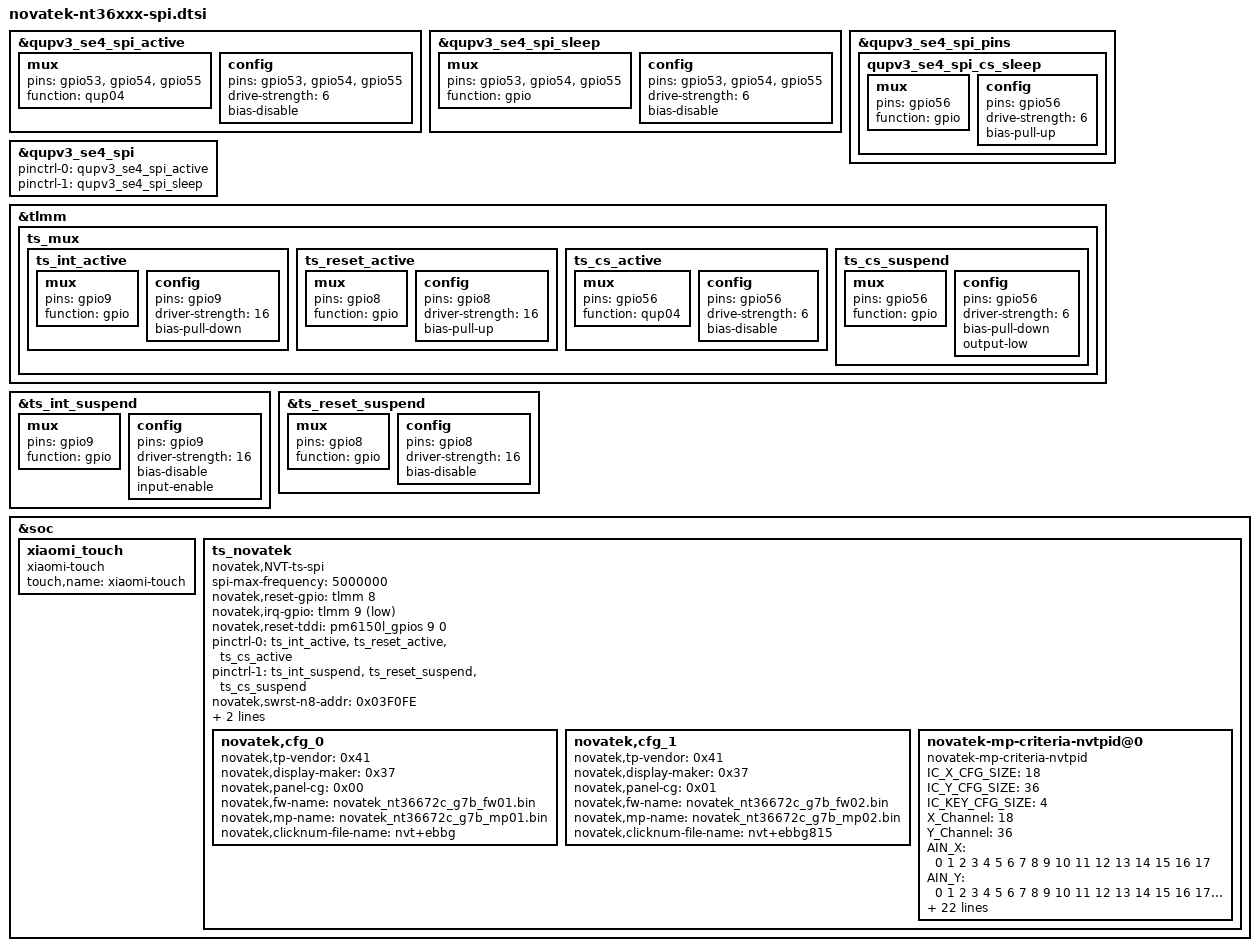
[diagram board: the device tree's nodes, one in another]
/*
 * Copyright (C) 2010 - 2017 Novatek, Inc.
 * Copyright (C) 2021 XiaoMi, Inc.
 *
 * $Revision$
 * $Date$
 *
 * This program is free software; you can redistribute it and/or modify
 * it under the terms of the GNU General Public License as published by
 * the Free Software Foundation; either version 2 of the License, or
 * (at your option) any later version.
 *
 * This program is distributed in the hope that it will be useful, but WITHOUT
 * ANY WARRANTY; without even the implied warranty of MERCHANTABILITY or
 * FITNESS FOR A PARTICULAR PURPOSE.  See the GNU General Public License for
 * more details.
 *
 */

/*spi init*/
&qupv3_se4_spi_active {
	mux {
		pins = "gpio53", "gpio54", "gpio55";
		function = "qup04";
	};

	config {
		pins = "gpio53", "gpio54", "gpio55";
		drive-strength = <6>;
		bias-disable;
	};
};

&qupv3_se4_spi_sleep {
	mux {
		pins = "gpio53", "gpio54", "gpio55";
		function = "gpio";
	};

	config {
		pins = "gpio53", "gpio54", "gpio55";
		drive-strength = <6>;
		bias-disable;
	};
};

&qupv3_se4_spi_pins {
	qupv3_se4_spi_cs_sleep: qupv3_se4_spi_cs_sleep {
	mux {
		pins = "gpio56";
		function = "gpio";
		};

		config {
			pins = "gpio56";
			drive-strength = <6>;
			bias-pull-up; /*CS IDLE PULL UP*/
		};
	};
};

&qupv3_se4_spi {
	pinctrl-0 = <&qupv3_se4_spi_active>;
	pinctrl-1 = <&qupv3_se4_spi_sleep>;
};


/*IC int pin, rst pin init*/
&tlmm {
	ts_mux {
		ts_int_active: ts_int_active {
			mux {
				pins = "gpio9";
				function = "gpio";
			};

			config {
				pins = "gpio9";
				driver-strength = <16>;
				bias-pull-down;
			};
		};

		ts_reset_active: ts_reset_active {
			mux {
				pins = "gpio8";
				function = "gpio";
			};

			config {
				pins = "gpio8";
				driver-strength = <16>;
				bias-pull-up;
			};
		};

		ts_cs_active: ts_cs_active {
			mux {
				pins = "gpio56";
				function = "qup04";
			};

			config {
				pins = "gpio56";
				drive-strength = <6>;
				bias-disable;
			};
		};

		ts_cs_suspend: ts_cs_suspend {
			mux {
				pins = "gpio56";
				function = "gpio";
			};

			config {
				pins = "gpio56";
				driver-strength = <6>;
				bias-pull-down;
				output-low;
			};
		};

	};
};

&ts_int_suspend {
	mux {
		pins = "gpio9";
		function = "gpio";
	};

	config {
		pins = "gpio9";
		driver-strength = <16>;
		bias-disable;
		input-enable;
	};
};

&ts_reset_suspend {
	mux {
		pins = "gpio8";
		function = "gpio";
	};

	config {
		pins = "gpio8";
		driver-strength = <16>;
		bias-disable;
	};
};


/* Novatek device tree node */
&soc {
	xiaomi_touch {
		compatible = "xiaomi-touch";
		status = "ok";
		touch,name = "xiaomi-touch";
	};

	ts_novatek {
			compatible = "novatek,NVT-ts-spi";
			status = "ok";

			spi-max-frequency = <5000000>;	//4800000,9600000,15000000,19200000 5M
			novatek,reset-gpio = <&tlmm 8 0x00>;
			novatek,irq-gpio = <&tlmm 9 0x2001>;
			novatek,reset-tddi = <&pm6150l_gpios 9 0>;
			pinctrl-names = "pmx_ts_active", "pmx_ts_suspend";
			pinctrl-0 = <&ts_int_active &ts_reset_active &ts_cs_active>;
			pinctrl-1 = <&ts_int_suspend &ts_reset_suspend &ts_cs_suspend>;

			/* 672 */
			//novatek,swrst-n8-addr = <0x01F01A>;

			/* 672A */
			novatek,swrst-n8-addr = <0x03F0FE>;
			novatek,spi-rd-fast-addr = <0x03F310>;

			novatek,config-array-size = <2>;
			novatek,cfg_0 {
				novatek,tp-vendor = <0x41>;
				novatek,display-maker = <0x37>;
				novatek,panel-cg = <0x00>;
				novatek,fw-name = "novatek_nt36672c_g7b_fw01.bin";
				novatek,mp-name = "novatek_nt36672c_g7b_mp01.bin";
				novatek,clicknum-file-name = "nvt+ebbg";
			};
			novatek,cfg_1 {
				novatek,tp-vendor = <0x41>;
				novatek,display-maker = <0x37>;
				novatek,panel-cg = <0x01>;
				novatek,fw-name = "novatek_nt36672c_g7b_fw02.bin";
				novatek,mp-name = "novatek_nt36672c_g7b_mp02.bin";
				novatek,clicknum-file-name = "nvt+ebbg815";
			};
			/* MP */
			//novatek,mp-support-dt;


			novatek-mp-criteria-nvtpid@0 {
				#address-cells = <1>;
				#size-cells = <0>;
				compatible = "novatek-mp-criteria-nvtpid";

				/* MP Config */
				IC_X_CFG_SIZE = <18>;
				IC_Y_CFG_SIZE = <36>;
				IC_KEY_CFG_SIZE = <4>;
				X_Channel = <18>;
				Y_Channel = <36>;
				AIN_X = <0 1 2 3 4 5 6 7 8 9 10 11 12 13 14 15 16 17>;
				AIN_Y = <0 1 2 3 4 5 6 7 8 9 10 11 12 13 14 15 16 17
							18 19 20 21 22 23 24 25 26 27 28 29 30 31 32 33 34 35>;
				AIN_KEY = <0 1 2 0xFF>;

				/* MP Criteria */
				PS_Config_Lmt_Short_Rawdata_P = <
					14008 14008 14008 14008 14008 14008 14008 14008 14008 14008 14008 14008 14008 14008 14008 14008 14008 14008
					14008 14008 14008 14008 14008 14008 14008 14008 14008 14008 14008 14008 14008 14008 14008 14008 14008 14008
					14008 14008 14008 14008 14008 14008 14008 14008 14008 14008 14008 14008 14008 14008 14008 14008 14008 14008
					14008 14008 14008 14008 14008 14008 14008 14008 14008 14008 14008 14008 14008 14008 14008 14008 14008 14008
					14008 14008 14008 14008 14008 14008 14008 14008 14008 14008 14008 14008 14008 14008 14008 14008 14008 14008
					14008 14008 14008 14008 14008 14008 14008 14008 14008 14008 14008 14008 14008 14008 14008 14008 14008 14008
					14008 14008 14008 14008 14008 14008 14008 14008 14008 14008 14008 14008 14008 14008 14008 14008 14008 14008
					14008 14008 14008 14008 14008 14008 14008 14008 14008 14008 14008 14008 14008 14008 14008 14008 14008 14008
					14008 14008 14008 14008 14008 14008 14008 14008 14008 14008 14008 14008 14008 14008 14008 14008 14008 14008
					14008 14008 14008 14008 14008 14008 14008 14008 14008 14008 14008 14008 14008 14008 14008 14008 14008 14008
					14008 14008 14008 14008 14008 14008 14008 14008 14008 14008 14008 14008 14008 14008 14008 14008 14008 14008
					14008 14008 14008 14008 14008 14008 14008 14008 14008 14008 14008 14008 14008 14008 14008 14008 14008 14008
					14008 14008 14008 14008 14008 14008 14008 14008 14008 14008 14008 14008 14008 14008 14008 14008 14008 14008
					14008 14008 14008 14008 14008 14008 14008 14008 14008 14008 14008 14008 14008 14008 14008 14008 14008 14008
					14008 14008 14008 14008 14008 14008 14008 14008 14008 14008 14008 14008 14008 14008 14008 14008 14008 14008
					14008 14008 14008 14008 14008 14008 14008 14008 14008 14008 14008 14008 14008 14008 14008 14008 14008 14008
					14008 14008 14008 14008 14008 14008 14008 14008 14008 14008 14008 14008 14008 14008 14008 14008 14008 14008
					14008 14008 14008 14008 14008 14008 14008 14008 14008 14008 14008 14008 14008 14008 14008 14008 14008 14008
					14008 14008 14008 14008 14008 14008 14008 14008 14008 14008 14008 14008 14008 14008 14008 14008 14008 14008
					14008 14008 14008 14008 14008 14008 14008 14008 14008 14008 14008 14008 14008 14008 14008 14008 14008 14008
					14008 14008 14008 14008 14008 14008 14008 14008 14008 14008 14008 14008 14008 14008 14008 14008 14008 14008
					14008 14008 14008 14008 14008 14008 14008 14008 14008 14008 14008 14008 14008 14008 14008 14008 14008 14008
					14008 14008 14008 14008 14008 14008 14008 14008 14008 14008 14008 14008 14008 14008 14008 14008 14008 14008
					14008 14008 14008 14008 14008 14008 14008 14008 14008 14008 14008 14008 14008 14008 14008 14008 14008 14008
					14008 14008 14008 14008 14008 14008 14008 14008 14008 14008 14008 14008 14008 14008 14008 14008 14008 14008
					14008 14008 14008 14008 14008 14008 14008 14008 14008 14008 14008 14008 14008 14008 14008 14008 14008 14008
					14008 14008 14008 14008 14008 14008 14008 14008 14008 14008 14008 14008 14008 14008 14008 14008 14008 14008
					14008 14008 14008 14008 14008 14008 14008 14008 14008 14008 14008 14008 14008 14008 14008 14008 14008 14008
					14008 14008 14008 14008 14008 14008 14008 14008 14008 14008 14008 14008 14008 14008 14008 14008 14008 14008
					14008 14008 14008 14008 14008 14008 14008 14008 14008 14008 14008 14008 14008 14008 14008 14008 14008 14008
					14008 14008 14008 14008 14008 14008 14008 14008 14008 14008 14008 14008 14008 14008 14008 14008 14008 14008
					14008 14008 14008 14008 14008 14008 14008 14008 14008 14008 14008 14008 14008 14008 14008 14008 14008 14008
					14008 14008 14008 14008 14008 14008 14008 14008 14008 14008 14008 14008 14008 14008 14008 14008 14008 14008
					14008 14008 14008 14008 14008 14008 14008 14008 14008 14008 14008 14008 14008 14008 14008 14008 14008 14008
					14008 14008 14008 14008 14008 14008 14008 14008 14008 14008 14008 14008 14008 14008 14008 14008 14008 14008
					14008 14008 14008 14008 14008 14008 14008 14008 14008 14008 14008 14008 14008 14008 14008 14008 14008 14008
					14008 14008 14008>;

				PS_Config_Lmt_Short_Rawdata_N = <
					10000 10000 10000 10000 10000 10000 10000 10000 10000 10000 10000 10000 10000 10000 10000 10000 10000 10000
					10000 10000 10000 10000 10000 10000 10000 10000 10000 10000 10000 10000 10000 10000 10000 10000 10000 10000
					10000 10000 10000 10000 10000 10000 10000 10000 10000 10000 10000 10000 10000 10000 10000 10000 10000 10000
					10000 10000 10000 10000 10000 10000 10000 10000 10000 10000 10000 10000 10000 10000 10000 10000 10000 10000
					10000 10000 10000 10000 10000 10000 10000 10000 10000 10000 10000 10000 10000 10000 10000 10000 10000 10000
					10000 10000 10000 10000 10000 10000 10000 10000 10000 10000 10000 10000 10000 10000 10000 10000 10000 10000
					10000 10000 10000 10000 10000 10000 10000 10000 10000 10000 10000 10000 10000 10000 10000 10000 10000 10000
					10000 10000 10000 10000 10000 10000 10000 10000 10000 10000 10000 10000 10000 10000 10000 10000 10000 10000
					10000 10000 10000 10000 10000 10000 10000 10000 10000 10000 10000 10000 10000 10000 10000 10000 10000 10000
					10000 10000 10000 10000 10000 10000 10000 10000 10000 10000 10000 10000 10000 10000 10000 10000 10000 10000
					10000 10000 10000 10000 10000 10000 10000 10000 10000 10000 10000 10000 10000 10000 10000 10000 10000 10000
					10000 10000 10000 10000 10000 10000 10000 10000 10000 10000 10000 10000 10000 10000 10000 10000 10000 10000
					10000 10000 10000 10000 10000 10000 10000 10000 10000 10000 10000 10000 10000 10000 10000 10000 10000 10000
					10000 10000 10000 10000 10000 10000 10000 10000 10000 10000 10000 10000 10000 10000 10000 10000 10000 10000
					10000 10000 10000 10000 10000 10000 10000 10000 10000 10000 10000 10000 10000 10000 10000 10000 10000 10000
					10000 10000 10000 10000 10000 10000 10000 10000 10000 10000 10000 10000 10000 10000 10000 10000 10000 10000
					10000 10000 10000 10000 10000 10000 10000 10000 10000 10000 10000 10000 10000 10000 10000 10000 10000 10000
					10000 10000 10000 10000 10000 10000 10000 10000 10000 10000 10000 10000 10000 10000 10000 10000 10000 10000
					10000 10000 10000 10000 10000 10000 10000 10000 10000 10000 10000 10000 10000 10000 10000 10000 10000 10000
					10000 10000 10000 10000 10000 10000 10000 10000 10000 10000 10000 10000 10000 10000 10000 10000 10000 10000
					10000 10000 10000 10000 10000 10000 10000 10000 10000 10000 10000 10000 10000 10000 10000 10000 10000 10000
					10000 10000 10000 10000 10000 10000 10000 10000 10000 10000 10000 10000 10000 10000 10000 10000 10000 10000
					10000 10000 10000 10000 10000 10000 10000 10000 10000 10000 10000 10000 10000 10000 10000 10000 10000 10000
					10000 10000 10000 10000 10000 10000 10000 10000 10000 10000 10000 10000 10000 10000 10000 10000 10000 10000
					10000 10000 10000 10000 10000 10000 10000 10000 10000 10000 10000 10000 10000 10000 10000 10000 10000 10000
					10000 10000 10000 10000 10000 10000 10000 10000 10000 10000 10000 10000 10000 10000 10000 10000 10000 10000
					10000 10000 10000 10000 10000 10000 10000 10000 10000 10000 10000 10000 10000 10000 10000 10000 10000 10000
					10000 10000 10000 10000 10000 10000 10000 10000 10000 10000 10000 10000 10000 10000 10000 10000 10000 10000
					10000 10000 10000 10000 10000 10000 10000 10000 10000 10000 10000 10000 10000 10000 10000 10000 10000 10000
					10000 10000 10000 10000 10000 10000 10000 10000 10000 10000 10000 10000 10000 10000 10000 10000 10000 10000
					10000 10000 10000 10000 10000 10000 10000 10000 10000 10000 10000 10000 10000 10000 10000 10000 10000 10000
					10000 10000 10000 10000 10000 10000 10000 10000 10000 10000 10000 10000 10000 10000 10000 10000 10000 10000
					10000 10000 10000 10000 10000 10000 10000 10000 10000 10000 10000 10000 10000 10000 10000 10000 10000 10000
					10000 10000 10000 10000 10000 10000 10000 10000 10000 10000 10000 10000 10000 10000 10000 10000 10000 10000
					10000 10000 10000 10000 10000 10000 10000 10000 10000 10000 10000 10000 10000 10000 10000 10000 10000 10000
					10000 10000 10000 10000 10000 10000 10000 10000 10000 10000 10000 10000 10000 10000 10000 10000 10000 10000
					10000 10000 10000>;

				PS_Config_Lmt_Open_Rawdata_P = <
					4096 4096 4096 4096 4096 4096 4096 4096 4096 4096 4096 4096 4096 4096 4096 4096 4096 4096
					4096 4096 4096 4096 4096 4096 4096 4096 4096 4096 4096 4096 4096 4096 4096 4096 4096 4096
					4096 4096 4096 4096 4096 4096 4096 4096 4096 4096 4096 4096 4096 4096 4096 4096 4096 4096
					4096 4096 4096 4096 4096 4096 4096 4096 4096 4096 4096 4096 4096 4096 4096 4096 4096 4096
					4096 4096 4096 4096 4096 4096 4096 4096 4096 4096 4096 4096 4096 4096 4096 4096 4096 4096
					4096 4096 4096 4096 4096 4096 4096 4096 4096 4096 4096 4096 4096 4096 4096 4096 4096 4096
					4096 4096 4096 4096 4096 4096 4096 4096 4096 4096 4096 4096 4096 4096 4096 4096 4096 4096
					4096 4096 4096 4096 4096 4096 4096 4096 4096 4096 4096 4096 4096 4096 4096 4096 4096 4096
					4096 4096 4096 4096 4096 4096 4096 4096 4096 4096 4096 4096 4096 4096 4096 4096 4096 4096
					4096 4096 4096 4096 4096 4096 4096 4096 4096 4096 4096 4096 4096 4096 4096 4096 4096 4096
					4096 4096 4096 4096 4096 4096 4096 4096 4096 4096 4096 4096 4096 4096 4096 4096 4096 4096
					4096 4096 4096 4096 4096 4096 4096 4096 4096 4096 4096 4096 4096 4096 4096 4096 4096 4096
					4096 4096 4096 4096 4096 4096 4096 4096 4096 4096 4096 4096 4096 4096 4096 4096 4096 4096
					4096 4096 4096 4096 4096 4096 4096 4096 4096 4096 4096 4096 4096 4096 4096 4096 4096 4096
					4096 4096 4096 4096 4096 4096 4096 4096 4096 4096 4096 4096 4096 4096 4096 4096 4096 4096
					4096 4096 4096 4096 4096 4096 4096 4096 4096 4096 4096 4096 4096 4096 4096 4096 4096 4096
					4096 4096 4096 4096 4096 4096 4096 4096 4096 4096 4096 4096 4096 4096 4096 4096 4096 4096
					4096 4096 4096 4096 4096 4096 4096 4096 4096 4096 4096 4096 4096 4096 4096 4096 4096 4096
					4096 4096 4096 4096 4096 4096 4096 4096 4096 4096 4096 4096 4096 4096 4096 4096 4096 4096
					4096 4096 4096 4096 4096 4096 4096 4096 4096 4096 4096 4096 4096 4096 4096 4096 4096 4096
					4096 4096 4096 4096 4096 4096 4096 4096 4096 4096 4096 4096 4096 4096 4096 4096 4096 4096
					4096 4096 4096 4096 4096 4096 4096 4096 4096 4096 4096 4096 4096 4096 4096 4096 4096 4096
					4096 4096 4096 4096 4096 4096 4096 4096 4096 4096 4096 4096 4096 4096 4096 4096 4096 4096
					4096 4096 4096 4096 4096 4096 4096 4096 4096 4096 4096 4096 4096 4096 4096 4096 4096 4096
					4096 4096 4096 4096 4096 4096 4096 4096 4096 4096 4096 4096 4096 4096 4096 4096 4096 4096
					4096 4096 4096 4096 4096 4096 4096 4096 4096 4096 4096 4096 4096 4096 4096 4096 4096 4096
					4096 4096 4096 4096 4096 4096 4096 4096 4096 4096 4096 4096 4096 4096 4096 4096 4096 4096
					4096 4096 4096 4096 4096 4096 4096 4096 4096 4096 4096 4096 4096 4096 4096 4096 4096 4096
					4096 4096 4096 4096 4096 4096 4096 4096 4096 4096 4096 4096 4096 4096 4096 4096 4096 4096
					4096 4096 4096 4096 4096 4096 4096 4096 4096 4096 4096 4096 4096 4096 4096 4096 4096 4096
					4096 4096 4096 4096 4096 4096 4096 4096 4096 4096 4096 4096 4096 4096 4096 4096 4096 4096
					4096 4096 4096 4096 4096 4096 4096 4096 4096 4096 4096 4096 4096 4096 4096 4096 4096 4096
					4096 4096 4096 4096 4096 4096 4096 4096 4096 4096 4096 4096 4096 4096 4096 4096 4096 4096
					4096 4096 4096 4096 4096 4096 4096 4096 4096 4096 4096 4096 4096 4096 4096 4096 4096 4096
					4096 4096 4096 4096 4096 4096 4096 4096 4096 4096 4096 4096 4096 4096 4096 4096 4096 4096
					4096 4096 4096 4096 4096 4096 4096 4096 4096 4096 4096 4096 4096 4096 4096 4096 4096 4096
					4096 4096 4096>;

				PS_Config_Lmt_Open_Rawdata_N = <
					50 50 50 50 50 50 50 50 50 50 50 50 50 50 50 50 50 50
					50 50 50 50 50 50 50 50 50 50 50 50 50 50 50 50 50 50
					50 50 50 50 50 50 50 50 50 50 50 50 50 50 50 50 50 50
					50 50 50 50 50 50 50 50 50 50 50 50 50 50 50 50 50 50
					50 50 50 50 50 50 50 50 50 50 50 50 50 50 50 50 50 50
					50 50 50 50 50 50 50 50 50 50 50 50 50 50 50 50 50 50
					50 50 50 50 50 50 50 50 50 50 50 50 50 50 50 50 50 50
					50 50 50 50 50 50 50 50 50 50 50 50 50 50 50 50 50 50
					50 50 50 50 50 50 50 50 50 50 50 50 50 50 50 50 50 50
					50 50 50 50 50 50 50 50 50 50 50 50 50 50 50 50 50 50
					50 50 50 50 50 50 50 50 50 50 50 50 50 50 50 50 50 50
					50 50 50 50 50 50 50 50 50 50 50 50 50 50 50 50 50 50
					50 50 50 50 50 50 50 50 50 50 50 50 50 50 50 50 50 50
					50 50 50 50 50 50 50 50 50 50 50 50 50 50 50 50 50 50
					50 50 50 50 50 50 50 50 50 50 50 50 50 50 50 50 50 50
					50 50 50 50 50 50 50 50 50 50 50 50 50 50 50 50 50 50
					50 50 50 50 50 50 50 50 50 50 50 50 50 50 50 50 50 50
					50 50 50 50 50 50 50 50 50 50 50 50 50 50 50 50 50 50
					50 50 50 50 50 50 50 50 50 50 50 50 50 50 50 50 50 50
					50 50 50 50 50 50 50 50 50 50 50 50 50 50 50 50 50 50
					50 50 50 50 50 50 50 50 50 50 50 50 50 50 50 50 50 50
					50 50 50 50 50 50 50 50 50 50 50 50 50 50 50 50 50 50
					50 50 50 50 50 50 50 50 50 50 50 50 50 50 50 50 50 50
					50 50 50 50 50 50 50 50 50 50 50 50 50 50 50 50 50 50
					50 50 50 50 50 50 50 50 50 50 50 50 50 50 50 50 50 50
					50 50 50 50 50 50 50 50 50 50 50 50 50 50 50 50 50 50
					50 50 50 50 50 50 50 50 50 50 50 50 50 50 50 50 50 50
					50 50 50 50 50 50 50 50 50 50 50 50 50 50 50 50 50 50
					50 50 50 50 50 50 50 50 50 50 50 50 50 50 50 50 50 50
					50 50 50 50 50 50 50 50 50 50 50 50 50 50 50 50 50 50
					50 50 50 50 50 50 50 50 50 50 50 50 50 50 50 50 50 50
					50 50 50 50 50 50 50 50 50 50 50 50 50 50 50 50 50 50
					50 50 50 50 50 50 50 50 50 50 50 50 50 50 50 50 50 50
					50 50 50 50 50 50 50 50 50 50 50 50 50 50 50 50 50 50
					50 50 50 50 50 50 50 50 50 50 50 50 50 50 50 50 50 50
					50 50 50 50 50 50 50 50 50 50 50 50 50 50 50 50 50 50
					50 50 50>;

				PS_Config_Lmt_FW_Rawdata_P = <
					1920 1920 1920 1920 1920 1920 1920 1920 1920 1920 1920 1920 1920 1920 1920 1920 1920 1920
					1920 1920 1920 1920 1920 1920 1920 1920 1920 1920 1920 1920 1920 1920 1920 1920 1920 1920
					1920 1920 1920 1920 1920 1920 1920 1920 1920 1920 1920 1920 1920 1920 1920 1920 1920 1920
					1920 1920 1920 1920 1920 1920 1920 1920 1920 1920 1920 1920 1920 1920 1920 1920 1920 1920
					1920 1920 1920 1920 1920 1920 1920 1920 1920 1920 1920 1920 1920 1920 1920 1920 1920 1920
					1920 1920 1920 1920 1920 1920 1920 1920 1920 1920 1920 1920 1920 1920 1920 1920 1920 1920
					1920 1920 1920 1920 1920 1920 1920 1920 1920 1920 1920 1920 1920 1920 1920 1920 1920 1920
					1920 1920 1920 1920 1920 1920 1920 1920 1920 1920 1920 1920 1920 1920 1920 1920 1920 1920
					1920 1920 1920 1920 1920 1920 1920 1920 1920 1920 1920 1920 1920 1920 1920 1920 1920 1920
					1920 1920 1920 1920 1920 1920 1920 1920 1920 1920 1920 1920 1920 1920 1920 1920 1920 1920
					1920 1920 1920 1920 1920 1920 1920 1920 1920 1920 1920 1920 1920 1920 1920 1920 1920 1920
					1920 1920 1920 1920 1920 1920 1920 1920 1920 1920 1920 1920 1920 1920 1920 1920 1920 1920
					1920 1920 1920 1920 1920 1920 1920 1920 1920 1920 1920 1920 1920 1920 1920 1920 1920 1920
					1920 1920 1920 1920 1920 1920 1920 1920 1920 1920 1920 1920 1920 1920 1920 1920 1920 1920
					1920 1920 1920 1920 1920 1920 1920 1920 1920 1920 1920 1920 1920 1920 1920 1920 1920 1920
					1920 1920 1920 1920 1920 1920 1920 1920 1920 1920 1920 1920 1920 1920 1920 1920 1920 1920
					1920 1920 1920 1920 1920 1920 1920 1920 1920 1920 1920 1920 1920 1920 1920 1920 1920 1920
					1920 1920 1920 1920 1920 1920 1920 1920 1920 1920 1920 1920 1920 1920 1920 1920 1920 1920
					1920 1920 1920 1920 1920 1920 1920 1920 1920 1920 1920 1920 1920 1920 1920 1920 1920 1920
					1920 1920 1920 1920 1920 1920 1920 1920 1920 1920 1920 1920 1920 1920 1920 1920 1920 1920
					1920 1920 1920 1920 1920 1920 1920 1920 1920 1920 1920 1920 1920 1920 1920 1920 1920 1920
					1920 1920 1920 1920 1920 1920 1920 1920 1920 1920 1920 1920 1920 1920 1920 1920 1920 1920
					1920 1920 1920 1920 1920 1920 1920 1920 1920 1920 1920 1920 1920 1920 1920 1920 1920 1920
					1920 1920 1920 1920 1920 1920 1920 1920 1920 1920 1920 1920 1920 1920 1920 1920 1920 1920
					1920 1920 1920 1920 1920 1920 1920 1920 1920 1920 1920 1920 1920 1920 1920 1920 1920 1920
					1920 1920 1920 1920 1920 1920 1920 1920 1920 1920 1920 1920 1920 1920 1920 1920 1920 1920
					1920 1920 1920 1920 1920 1920 1920 1920 1920 1920 1920 1920 1920 1920 1920 1920 1920 1920
					1920 1920 1920 1920 1920 1920 1920 1920 1920 1920 1920 1920 1920 1920 1920 1920 1920 1920
					1920 1920 1920 1920 1920 1920 1920 1920 1920 1920 1920 1920 1920 1920 1920 1920 1920 1920
					1920 1920 1920 1920 1920 1920 1920 1920 1920 1920 1920 1920 1920 1920 1920 1920 1920 1920
					1920 1920 1920 1920 1920 1920 1920 1920 1920 1920 1920 1920 1920 1920 1920 1920 1920 1920
					1920 1920 1920 1920 1920 1920 1920 1920 1920 1920 1920 1920 1920 1920 1920 1920 1920 1920
					1920 1920 1920 1920 1920 1920 1920 1920 1920 1920 1920 1920 1920 1920 1920 1920 1920 1920
					1920 1920 1920 1920 1920 1920 1920 1920 1920 1920 1920 1920 1920 1920 1920 1920 1920 1920
					1920 1920 1920 1920 1920 1920 1920 1920 1920 1920 1920 1920 1920 1920 1920 1920 1920 1920
					1920 1920 1920 1920 1920 1920 1920 1920 1920 1920 1920 1920 1920 1920 1920 1920 1920 1920
					1920 1920 1920>;

				PS_Config_Lmt_FW_Rawdata_N = <
					240 240 240 240 240 240 240 240 240 240 240 240 240 240 240 240 240 240
					240 240 240 240 240 240 240 240 240 240 240 240 240 240 240 240 240 240
					240 240 240 240 240 240 240 240 240 240 240 240 240 240 240 240 240 240
					240 240 240 240 240 240 240 240 240 240 240 240 240 240 240 240 240 240
					240 240 240 240 240 240 240 240 240 240 240 240 240 240 240 240 240 240
					240 240 240 240 240 240 240 240 240 240 240 240 240 240 240 240 240 240
					240 240 240 240 240 240 240 240 240 240 240 240 240 240 240 240 240 240
					240 240 240 240 240 240 240 240 240 240 240 240 240 240 240 240 240 240
					240 240 240 240 240 240 240 240 240 240 240 240 240 240 240 240 240 240
					240 240 240 240 240 240 240 240 240 240 240 240 240 240 240 240 240 240
					240 240 240 240 240 240 240 240 240 240 240 240 240 240 240 240 240 240
					240 240 240 240 240 240 240 240 240 240 240 240 240 240 240 240 240 240
					240 240 240 240 240 240 240 240 240 240 240 240 240 240 240 240 240 240
					240 240 240 240 240 240 240 240 240 240 240 240 240 240 240 240 240 240
					240 240 240 240 240 240 240 240 240 240 240 240 240 240 240 240 240 240
					240 240 240 240 240 240 240 240 240 240 240 240 240 240 240 240 240 240
					240 240 240 240 240 240 240 240 240 240 240 240 240 240 240 240 240 240
					240 240 240 240 240 240 240 240 240 240 240 240 240 240 240 240 240 240
					240 240 240 240 240 240 240 240 240 240 240 240 240 240 240 240 240 240
					240 240 240 240 240 240 240 240 240 240 240 240 240 240 240 240 240 240
					240 240 240 240 240 240 240 240 240 240 240 240 240 240 240 240 240 240
					240 240 240 240 240 240 240 240 240 240 240 240 240 240 240 240 240 240
					240 240 240 240 240 240 240 240 240 240 240 240 240 240 240 240 240 240
					240 240 240 240 240 240 240 240 240 240 240 240 240 240 240 240 240 240
					240 240 240 240 240 240 240 240 240 240 240 240 240 240 240 240 240 240
					240 240 240 240 240 240 240 240 240 240 240 240 240 240 240 240 240 240
					240 240 240 240 240 240 240 240 240 240 240 240 240 240 240 240 240 240
					240 240 240 240 240 240 240 240 240 240 240 240 240 240 240 240 240 240
					240 240 240 240 240 240 240 240 240 240 240 240 240 240 240 240 240 240
					240 240 240 240 240 240 240 240 240 240 240 240 240 240 240 240 240 240
					240 240 240 240 240 240 240 240 240 240 240 240 240 240 240 240 240 240
					240 240 240 240 240 240 240 240 240 240 240 240 240 240 240 240 240 240
					240 240 240 240 240 240 240 240 240 240 240 240 240 240 240 240 240 240
					240 240 240 240 240 240 240 240 240 240 240 240 240 240 240 240 240 240
					240 240 240 240 240 240 240 240 240 240 240 240 240 240 240 240 240 240
					240 240 240 240 240 240 240 240 240 240 240 240 240 240 240 240 240 240
					240 240 240>;

				PS_Config_Lmt_FW_CC_P = <
					314 314 314 314 314 314 314 314 314 314 314 314 314 314 314 314 314 314
					314 314 314 314 314 314 314 314 314 314 314 314 314 314 314 314 314 314
					314 314 314 314 314 314 314 314 314 314 314 314 314 314 314 314 314 314
					314 314 314 314 314 314 314 314 314 314 314 314 314 314 314 314 314 314
					314 314 314 314 314 314 314 314 314 314 314 314 314 314 314 314 314 314
					314 314 314 314 314 314 314 314 314 314 314 314 314 314 314 314 314 314
					314 314 314 314 314 314 314 314 314 314 314 314 314 314 314 314 314 314
					314 314 314 314 314 314 314 314 314 314 314 314 314 314 314 314 314 314
					314 314 314 314 314 314 314 314 314 314 314 314 314 314 314 314 314 314
					314 314 314 314 314 314 314 314 314 314 314 314 314 314 314 314 314 314
					314 314 314 314 314 314 314 314 314 314 314 314 314 314 314 314 314 314
					314 314 314 314 314 314 314 314 314 314 314 314 314 314 314 314 314 314
					314 314 314 314 314 314 314 314 314 314 314 314 314 314 314 314 314 314
					314 314 314 314 314 314 314 314 314 314 314 314 314 314 314 314 314 314
					314 314 314 314 314 314 314 314 314 314 314 314 314 314 314 314 314 314
					314 314 314 314 314 314 314 314 314 314 314 314 314 314 314 314 314 314
					314 314 314 314 314 314 314 314 314 314 314 314 314 314 314 314 314 314
					314 314 314 314 314 314 314 314 314 314 314 314 314 314 314 314 314 314
					314 314 314 314 314 314 314 314 314 314 314 314 314 314 314 314 314 314
					314 314 314 314 314 314 314 314 314 314 314 314 314 314 314 314 314 314
					314 314 314 314 314 314 314 314 314 314 314 314 314 314 314 314 314 314
					314 314 314 314 314 314 314 314 314 314 314 314 314 314 314 314 314 314
					314 314 314 314 314 314 314 314 314 314 314 314 314 314 314 314 314 314
					314 314 314 314 314 314 314 314 314 314 314 314 314 314 314 314 314 314
					314 314 314 314 314 314 314 314 314 314 314 314 314 314 314 314 314 314
					314 314 314 314 314 314 314 314 314 314 314 314 314 314 314 314 314 314
					314 314 314 314 314 314 314 314 314 314 314 314 314 314 314 314 314 314
					314 314 314 314 314 314 314 314 314 314 314 314 314 314 314 314 314 314
					314 314 314 314 314 314 314 314 314 314 314 314 314 314 314 314 314 314
					314 314 314 314 314 314 314 314 314 314 314 314 314 314 314 314 314 314
					314 314 314 314 314 314 314 314 314 314 314 314 314 314 314 314 314 314
					314 314 314 314 314 314 314 314 314 314 314 314 314 314 314 314 314 314
					314 314 314 314 314 314 314 314 314 314 314 314 314 314 314 314 314 314
					314 314 314 314 314 314 314 314 314 314 314 314 314 314 314 314 314 314
					314 314 314 314 314 314 314 314 314 314 314 314 314 314 314 314 314 314
					314 314 314 314 314 314 314 314 314 314 314 314 314 314 314 314 314 314
					314 314 314>;

				PS_Config_Lmt_FW_CC_N = <
					30 30 30 30 30 30 30 30 30 30 30 30 30 30 30 30 30 30
					30 30 30 30 30 30 30 30 30 30 30 30 30 30 30 30 30 30
					30 30 30 30 30 30 30 30 30 30 30 30 30 30 30 30 30 30
					30 30 30 30 30 30 30 30 30 30 30 30 30 30 30 30 30 30
					30 30 30 30 30 30 30 30 30 30 30 30 30 30 30 30 30 30
					30 30 30 30 30 30 30 30 30 30 30 30 30 30 30 30 30 30
					30 30 30 30 30 30 30 30 30 30 30 30 30 30 30 30 30 30
					30 30 30 30 30 30 30 30 30 30 30 30 30 30 30 30 30 30
					30 30 30 30 30 30 30 30 30 30 30 30 30 30 30 30 30 30
					30 30 30 30 30 30 30 30 30 30 30 30 30 30 30 30 30 30
					30 30 30 30 30 30 30 30 30 30 30 30 30 30 30 30 30 30
					30 30 30 30 30 30 30 30 30 30 30 30 30 30 30 30 30 30
					30 30 30 30 30 30 30 30 30 30 30 30 30 30 30 30 30 30
					30 30 30 30 30 30 30 30 30 30 30 30 30 30 30 30 30 30
					30 30 30 30 30 30 30 30 30 30 30 30 30 30 30 30 30 30
					30 30 30 30 30 30 30 30 30 30 30 30 30 30 30 30 30 30
					30 30 30 30 30 30 30 30 30 30 30 30 30 30 30 30 30 30
					30 30 30 30 30 30 30 30 30 30 30 30 30 30 30 30 30 30
					30 30 30 30 30 30 30 30 30 30 30 30 30 30 30 30 30 30
					30 30 30 30 30 30 30 30 30 30 30 30 30 30 30 30 30 30
					30 30 30 30 30 30 30 30 30 30 30 30 30 30 30 30 30 30
					30 30 30 30 30 30 30 30 30 30 30 30 30 30 30 30 30 30
					30 30 30 30 30 30 30 30 30 30 30 30 30 30 30 30 30 30
					30 30 30 30 30 30 30 30 30 30 30 30 30 30 30 30 30 30
					30 30 30 30 30 30 30 30 30 30 30 30 30 30 30 30 30 30
					30 30 30 30 30 30 30 30 30 30 30 30 30 30 30 30 30 30
					30 30 30 30 30 30 30 30 30 30 30 30 30 30 30 30 30 30
					30 30 30 30 30 30 30 30 30 30 30 30 30 30 30 30 30 30
					30 30 30 30 30 30 30 30 30 30 30 30 30 30 30 30 30 30
					30 30 30 30 30 30 30 30 30 30 30 30 30 30 30 30 30 30
					30 30 30 30 30 30 30 30 30 30 30 30 30 30 30 30 30 30
					30 30 30 30 30 30 30 30 30 30 30 30 30 30 30 30 30 30
					30 30 30 30 30 30 30 30 30 30 30 30 30 30 30 30 30 30
					30 30 30 30 30 30 30 30 30 30 30 30 30 30 30 30 30 30
					30 30 30 30 30 30 30 30 30 30 30 30 30 30 30 30 30 30
					30 30 30 30 30 30 30 30 30 30 30 30 30 30 30 30 30 30
					30 30 30>;

				PS_Config_Lmt_FW_Diff_P = <
					75 75 75 75 75 75 75 75 75 75 75 75 75 75 75 75 75 75
					75 75 75 75 75 75 75 75 75 75 75 75 75 75 75 75 75 75
					75 75 75 75 75 75 75 75 75 75 75 75 75 75 75 75 75 75
					75 75 75 75 75 75 75 75 75 75 75 75 75 75 75 75 75 75
					75 75 75 75 75 75 75 75 75 75 75 75 75 75 75 75 75 75
					75 75 75 75 75 75 75 75 75 75 75 75 75 75 75 75 75 75
					75 75 75 75 75 75 75 75 75 75 75 75 75 75 75 75 75 75
					75 75 75 75 75 75 75 75 75 75 75 75 75 75 75 75 75 75
					75 75 75 75 75 75 75 75 75 75 75 75 75 75 75 75 75 75
					75 75 75 75 75 75 75 75 75 75 75 75 75 75 75 75 75 75
					75 75 75 75 75 75 75 75 75 75 75 75 75 75 75 75 75 75
					75 75 75 75 75 75 75 75 75 75 75 75 75 75 75 75 75 75
					75 75 75 75 75 75 75 75 75 75 75 75 75 75 75 75 75 75
					75 75 75 75 75 75 75 75 75 75 75 75 75 75 75 75 75 75
					75 75 75 75 75 75 75 75 75 75 75 75 75 75 75 75 75 75
					75 75 75 75 75 75 75 75 75 75 75 75 75 75 75 75 75 75
					75 75 75 75 75 75 75 75 75 75 75 75 75 75 75 75 75 75
					75 75 75 75 75 75 75 75 75 75 75 75 75 75 75 75 75 75
					75 75 75 75 75 75 75 75 75 75 75 75 75 75 75 75 75 75
					75 75 75 75 75 75 75 75 75 75 75 75 75 75 75 75 75 75
					75 75 75 75 75 75 75 75 75 75 75 75 75 75 75 75 75 75
					75 75 75 75 75 75 75 75 75 75 75 75 75 75 75 75 75 75
					75 75 75 75 75 75 75 75 75 75 75 75 75 75 75 75 75 75
					75 75 75 75 75 75 75 75 75 75 75 75 75 75 75 75 75 75
					75 75 75 75 75 75 75 75 75 75 75 75 75 75 75 75 75 75
					75 75 75 75 75 75 75 75 75 75 75 75 75 75 75 75 75 75
					75 75 75 75 75 75 75 75 75 75 75 75 75 75 75 75 75 75
					75 75 75 75 75 75 75 75 75 75 75 75 75 75 75 75 75 75
					75 75 75 75 75 75 75 75 75 75 75 75 75 75 75 75 75 75
					75 75 75 75 75 75 75 75 75 75 75 75 75 75 75 75 75 75
					75 75 75 75 75 75 75 75 75 75 75 75 75 75 75 75 75 75
					75 75 75 75 75 75 75 75 75 75 75 75 75 75 75 75 75 75
					75 75 75 75 75 75 75 75 75 75 75 75 75 75 75 75 75 75
					75 75 75 75 75 75 75 75 75 75 75 75 75 75 75 75 75 75
					75 75 75 75 75 75 75 75 75 75 75 75 75 75 75 75 75 75
					75 75 75 75 75 75 75 75 75 75 75 75 75 75 75 75 75 75
					75 75 75>;

				PS_Config_Lmt_FW_Diff_N = <
					(-75) (-75) (-75) (-75) (-75) (-75) (-75) (-75) (-75) (-75) (-75) (-75) (-75) (-75) (-75) (-75) (-75) (-75)
					(-75) (-75) (-75) (-75) (-75) (-75) (-75) (-75) (-75) (-75) (-75) (-75) (-75) (-75) (-75) (-75) (-75) (-75)
					(-75) (-75) (-75) (-75) (-75) (-75) (-75) (-75) (-75) (-75) (-75) (-75) (-75) (-75) (-75) (-75) (-75) (-75)
					(-75) (-75) (-75) (-75) (-75) (-75) (-75) (-75) (-75) (-75) (-75) (-75) (-75) (-75) (-75) (-75) (-75) (-75)
					(-75) (-75) (-75) (-75) (-75) (-75) (-75) (-75) (-75) (-75) (-75) (-75) (-75) (-75) (-75) (-75) (-75) (-75)
					(-75) (-75) (-75) (-75) (-75) (-75) (-75) (-75) (-75) (-75) (-75) (-75) (-75) (-75) (-75) (-75) (-75) (-75)
					(-75) (-75) (-75) (-75) (-75) (-75) (-75) (-75) (-75) (-75) (-75) (-75) (-75) (-75) (-75) (-75) (-75) (-75)
					(-75) (-75) (-75) (-75) (-75) (-75) (-75) (-75) (-75) (-75) (-75) (-75) (-75) (-75) (-75) (-75) (-75) (-75)
					(-75) (-75) (-75) (-75) (-75) (-75) (-75) (-75) (-75) (-75) (-75) (-75) (-75) (-75) (-75) (-75) (-75) (-75)
					(-75) (-75) (-75) (-75) (-75) (-75) (-75) (-75) (-75) (-75) (-75) (-75) (-75) (-75) (-75) (-75) (-75) (-75)
					(-75) (-75) (-75) (-75) (-75) (-75) (-75) (-75) (-75) (-75) (-75) (-75) (-75) (-75) (-75) (-75) (-75) (-75)
					(-75) (-75) (-75) (-75) (-75) (-75) (-75) (-75) (-75) (-75) (-75) (-75) (-75) (-75) (-75) (-75) (-75) (-75)
					(-75) (-75) (-75) (-75) (-75) (-75) (-75) (-75) (-75) (-75) (-75) (-75) (-75) (-75) (-75) (-75) (-75) (-75)
					(-75) (-75) (-75) (-75) (-75) (-75) (-75) (-75) (-75) (-75) (-75) (-75) (-75) (-75) (-75) (-75) (-75) (-75)
					(-75) (-75) (-75) (-75) (-75) (-75) (-75) (-75) (-75) (-75) (-75) (-75) (-75) (-75) (-75) (-75) (-75) (-75)
					(-75) (-75) (-75) (-75) (-75) (-75) (-75) (-75) (-75) (-75) (-75) (-75) (-75) (-75) (-75) (-75) (-75) (-75)
					(-75) (-75) (-75) (-75) (-75) (-75) (-75) (-75) (-75) (-75) (-75) (-75) (-75) (-75) (-75) (-75) (-75) (-75)
					(-75) (-75) (-75) (-75) (-75) (-75) (-75) (-75) (-75) (-75) (-75) (-75) (-75) (-75) (-75) (-75) (-75) (-75)
					(-75) (-75) (-75) (-75) (-75) (-75) (-75) (-75) (-75) (-75) (-75) (-75) (-75) (-75) (-75) (-75) (-75) (-75)
					(-75) (-75) (-75) (-75) (-75) (-75) (-75) (-75) (-75) (-75) (-75) (-75) (-75) (-75) (-75) (-75) (-75) (-75)
					(-75) (-75) (-75) (-75) (-75) (-75) (-75) (-75) (-75) (-75) (-75) (-75) (-75) (-75) (-75) (-75) (-75) (-75)
					(-75) (-75) (-75) (-75) (-75) (-75) (-75) (-75) (-75) (-75) (-75) (-75) (-75) (-75) (-75) (-75) (-75) (-75)
					(-75) (-75) (-75) (-75) (-75) (-75) (-75) (-75) (-75) (-75) (-75) (-75) (-75) (-75) (-75) (-75) (-75) (-75)
					(-75) (-75) (-75) (-75) (-75) (-75) (-75) (-75) (-75) (-75) (-75) (-75) (-75) (-75) (-75) (-75) (-75) (-75)
					(-75) (-75) (-75) (-75) (-75) (-75) (-75) (-75) (-75) (-75) (-75) (-75) (-75) (-75) (-75) (-75) (-75) (-75)
					(-75) (-75) (-75) (-75) (-75) (-75) (-75) (-75) (-75) (-75) (-75) (-75) (-75) (-75) (-75) (-75) (-75) (-75)
					(-75) (-75) (-75) (-75) (-75) (-75) (-75) (-75) (-75) (-75) (-75) (-75) (-75) (-75) (-75) (-75) (-75) (-75)
					(-75) (-75) (-75) (-75) (-75) (-75) (-75) (-75) (-75) (-75) (-75) (-75) (-75) (-75) (-75) (-75) (-75) (-75)
					(-75) (-75) (-75) (-75) (-75) (-75) (-75) (-75) (-75) (-75) (-75) (-75) (-75) (-75) (-75) (-75) (-75) (-75)
					(-75) (-75) (-75) (-75) (-75) (-75) (-75) (-75) (-75) (-75) (-75) (-75) (-75) (-75) (-75) (-75) (-75) (-75)
					(-75) (-75) (-75) (-75) (-75) (-75) (-75) (-75) (-75) (-75) (-75) (-75) (-75) (-75) (-75) (-75) (-75) (-75)
					(-75) (-75) (-75) (-75) (-75) (-75) (-75) (-75) (-75) (-75) (-75) (-75) (-75) (-75) (-75) (-75) (-75) (-75)
					(-75) (-75) (-75) (-75) (-75) (-75) (-75) (-75) (-75) (-75) (-75) (-75) (-75) (-75) (-75) (-75) (-75) (-75)
					(-75) (-75) (-75) (-75) (-75) (-75) (-75) (-75) (-75) (-75) (-75) (-75) (-75) (-75) (-75) (-75) (-75) (-75)
					(-75) (-75) (-75) (-75) (-75) (-75) (-75) (-75) (-75) (-75) (-75) (-75) (-75) (-75) (-75) (-75) (-75) (-75)
					(-75) (-75) (-75) (-75) (-75) (-75) (-75) (-75) (-75) (-75) (-75) (-75) (-75) (-75) (-75) (-75) (-75) (-75)
					(-75) (-75) (-75)>;

				PS_Config_Diff_Test_Frame = <50>;
			};
	};
};
